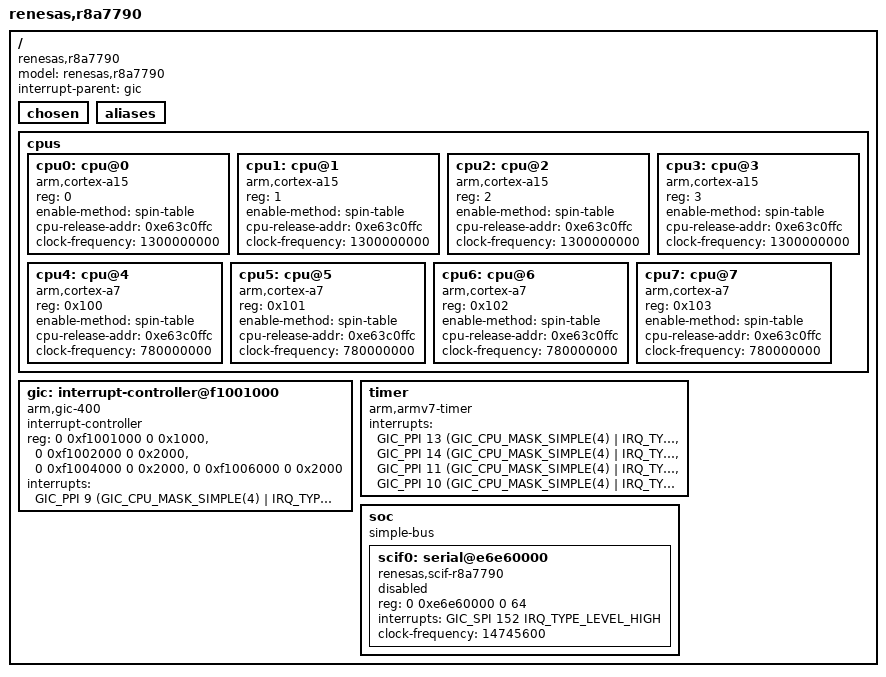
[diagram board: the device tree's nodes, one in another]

#include <dt-bindings/interrupt-controller/arm-gic.h>
#include <dt-bindings/interrupt-controller/irq.h>

/ {
	model = "renesas,r8a7790";
	compatible = "renesas,r8a7790";
	interrupt-parent = <&gic>;
	#address-cells = <2>;
	#size-cells = <2>;

	chosen { };

        aliases { };

	cpus {
		#address-cells = <1>;
		#size-cells = <0>;

		cpu0: cpu@0 {
			device_type = "cpu";
			compatible = "arm,cortex-a15";
			reg = <0>;
			enable-method = "spin-table";
			cpu-release-addr = <0xe63c0ffc>;
			clock-frequency = <1300000000>;
		};

		cpu1: cpu@1 {
			device_type = "cpu";
			compatible = "arm,cortex-a15";
			reg = <1>;
			enable-method = "spin-table";
			cpu-release-addr = <0xe63c0ffc>;
			clock-frequency = <1300000000>;
		};

		cpu2: cpu@2 {
			device_type = "cpu";
			compatible = "arm,cortex-a15";
			reg = <2>;
			enable-method = "spin-table";
			cpu-release-addr = <0xe63c0ffc>;
			clock-frequency = <1300000000>;
		};

		cpu3: cpu@3 {
			device_type = "cpu";
			compatible = "arm,cortex-a15";
			reg = <3>;
			enable-method = "spin-table";
			cpu-release-addr = <0xe63c0ffc>;
			clock-frequency = <1300000000>;
		};

		cpu4: cpu@4 {
			device_type = "cpu";
			compatible = "arm,cortex-a7";
			reg = <0x100>;
			enable-method = "spin-table";
			cpu-release-addr = <0xe63c0ffc>;
			clock-frequency = <780000000>;
		};

		cpu5: cpu@5 {
			device_type = "cpu";
			compatible = "arm,cortex-a7";
			reg = <0x101>;
			enable-method = "spin-table";
			cpu-release-addr = <0xe63c0ffc>;
			clock-frequency = <780000000>;
		};

		cpu6: cpu@6 {
			device_type = "cpu";
			compatible = "arm,cortex-a7";
			reg = <0x102>;
			enable-method = "spin-table";
			cpu-release-addr = <0xe63c0ffc>;
			clock-frequency = <780000000>;
		};

		cpu7: cpu@7 {
			device_type = "cpu";
			compatible = "arm,cortex-a7";
			reg = <0x103>;
			enable-method = "spin-table";
			cpu-release-addr = <0xe63c0ffc>;
			clock-frequency = <780000000>;
		};
	};

	gic: interrupt-controller@f1001000 {
		compatible = "arm,gic-400", "arm,cortex-a15-gic";
		#interrupt-cells = <3>;
		#address-cells = <0>;
		interrupt-controller;
		reg = <0 0xf1001000 0 0x1000>,
			<0 0xf1002000 0 0x2000>,
			<0 0xf1004000 0 0x2000>,
			<0 0xf1006000 0 0x2000>;
		interrupts = <GIC_PPI 9 (GIC_CPU_MASK_SIMPLE(4) | IRQ_TYPE_LEVEL_HIGH)>;
	};

	timer {
		compatible = "arm,armv7-timer";
		interrupts = <GIC_PPI 13 (GIC_CPU_MASK_SIMPLE(4) | IRQ_TYPE_LEVEL_LOW)>,
			     <GIC_PPI 14 (GIC_CPU_MASK_SIMPLE(4) | IRQ_TYPE_LEVEL_LOW)>,
			     <GIC_PPI 11 (GIC_CPU_MASK_SIMPLE(4) | IRQ_TYPE_LEVEL_LOW)>,
			     <GIC_PPI 10 (GIC_CPU_MASK_SIMPLE(4) | IRQ_TYPE_LEVEL_LOW)>;
	};

	soc {
		compatible = "simple-bus";
		#address-cells = <2>;
		#size-cells = <2>;

		scif0: serial@e6e60000 { /* FIXME: */
			compatible = "renesas,scif-r8a7790", "renesas,rcar-gen2-scif",
				     "renesas,scif";
			reg = <0 0xe6e60000 0 64>;
			interrupts = <GIC_SPI 152 IRQ_TYPE_LEVEL_HIGH>;
			status = "disabled";
			/* Only for Xvisor */
			clock-frequency = <14745600>;
		};
	};
};

